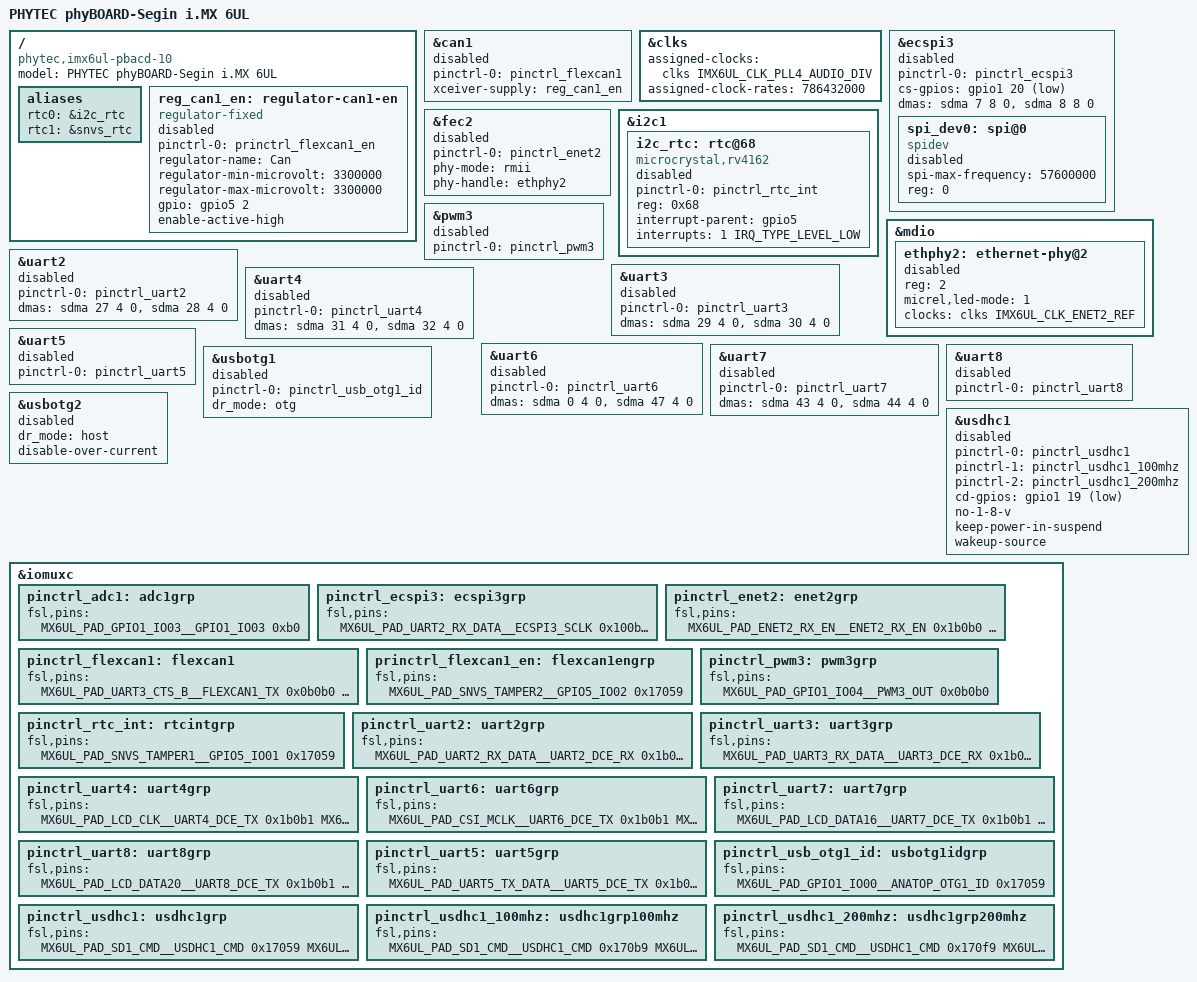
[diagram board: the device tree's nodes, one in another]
// SPDX-License-Identifier: (GPL-2.0+ OR MIT)
/*
 * Author: Llewellyn Fernandes <llewellynkbc@gmail.com>
 */

/ {

	model = "PHYTEC phyBOARD-Segin i.MX 6UL";
	compatible = "phytec,imx6ul-pbacd-10", "phytec,imx6ul-pcl063","fsl,imx6ul";

	aliases {
		rtc0 = &i2c_rtc;
		rtc1 = &snvs_rtc;
	};


	reg_can1_en: regulator-can1-en {
		compatible = "regulator-fixed";
		pinctrl-names = "default";
		pinctrl-0 = <&princtrl_flexcan1_en>;
		regulator-name = "Can";
		regulator-min-microvolt = <3300000>;
		regulator-max-microvolt = <3300000>;
		gpio = <&gpio5 2 GPIO_ACTIVE_HIGH>;
		enable-active-high;
		status = "disabled";
	};

};


&can1 {
	pinctrl-names = "default";
	pinctrl-0 = <&pinctrl_flexcan1>;
	xceiver-supply = <&reg_can1_en>;
	status = "disabled";
};

&clks {
	assigned-clocks = <&clks IMX6UL_CLK_PLL4_AUDIO_DIV>;
	assigned-clock-rates = <786432000>;
};


&ecspi3 {
	pinctrl-names = "default";
	pinctrl-0 = <&pinctrl_ecspi3>;
	cs-gpios = <&gpio1 20 GPIO_ACTIVE_LOW>;
	dmas = <&sdma 7 8 0>,
	       <&sdma 8 8 0>;
	dma-names = "rx", "tx";
	status = "disabled";

	spi_dev0: spi@0 {
		compatible = "spidev";
		spi-max-frequency = <57600000>;
		reg = <0>;
		status = "disabled";
	};
};

&fec2 {
	pinctrl-names = "default";
	pinctrl-0 = <&pinctrl_enet2>;
	phy-mode = "rmii";
	phy-handle = <&ethphy2>;
	status = "disabled";
};

&i2c1 {

	i2c_rtc: rtc@68 {
		pinctrl-names = "default";
		pinctrl-0 = <&pinctrl_rtc_int>;
		compatible = "microcrystal,rv4162";
		reg = <0x68>;
		interrupt-parent = <&gpio5>;
		interrupts = <1 IRQ_TYPE_LEVEL_LOW>;
		status = "disabled";
	};
};

&mdio {
	ethphy2: ethernet-phy@2 {
		reg = <2>;
		micrel,led-mode = <1>;
		clocks = <&clks IMX6UL_CLK_ENET2_REF>;
		clock-names = "rmii-ref";
		status = "disabled";
	};
};

&pwm3 {
	pinctrl-names = "default";
	pinctrl-0 = <&pinctrl_pwm3>;
	status = "disabled";
};


&uart2 {
	pinctrl-names = "default";
	pinctrl-0 = <&pinctrl_uart2>;
	dmas = <&sdma 27 4 0>,<&sdma 28 4 0>;
	dma-names = "rx","tx";
	status = "disabled";
};


&uart3 {
	pinctrl-names = "default";
	pinctrl-0 = <&pinctrl_uart3>;
	dmas = <&sdma 29 4 0>,<&sdma 30 4 0>;
	dma-names = "rx","tx";
	status = "disabled";
};


&uart4 {
	pinctrl-names = "default";
	pinctrl-0 = <&pinctrl_uart4>;
	dmas = <&sdma 31 4 0>,<&sdma 32 4 0>;
	dma-names = "rx","tx";
	status = "disabled";
};


&uart5 {
	pinctrl-names = "default";
	pinctrl-0 = <&pinctrl_uart5>;
	status = "disabled";
};


&uart6 {
	pinctrl-names = "default";
	pinctrl-0 = <&pinctrl_uart6>;
	dmas = <&sdma 0 4 0>,<&sdma 47 4 0>;
	dma-names = "rx","tx";
	status = "disabled";
};


&uart7 {
	pinctrl-names = "default";
	pinctrl-0 = <&pinctrl_uart7>;
	dmas = <&sdma 43 4 0>,<&sdma 44 4 0>;
	dma-names = "rx","tx";
	status = "disabled";
};


&uart8 {
	pinctrl-names = "default";
	pinctrl-0 = <&pinctrl_uart8>;
//	dmas = <&sdma 45 4 0>,<&sdma 46 4 0>;
//	dma-names = "rx","tx";
	status = "disabled";
};

&usbotg1 {
	pinctrl-names = "default";
	pinctrl-0 = <&pinctrl_usb_otg1_id>;
	dr_mode = "otg";
	status = "disabled";
};

&usbotg2 {
	dr_mode = "host";
	disable-over-current;
	status = "disabled";
};

&usdhc1 {
	pinctrl-names = "default", "state_100mhz", "state_200mhz";
	pinctrl-0 = <&pinctrl_usdhc1>;
	pinctrl-1 = <&pinctrl_usdhc1_100mhz>;
	pinctrl-2 = <&pinctrl_usdhc1_200mhz>;
	cd-gpios = <&gpio1 19 GPIO_ACTIVE_LOW>;
	no-1-8-v;
	keep-power-in-suspend;
	wakeup-source;
	status = "disabled";
};

&iomuxc {
	pinctrl_adc1: adc1grp {
		fsl,pins = <
			MX6UL_PAD_GPIO1_IO03__GPIO1_IO03	0xb0
		>;
	};

	pinctrl_ecspi3: ecspi3grp {
		fsl,pins = <
			MX6UL_PAD_UART2_RX_DATA__ECSPI3_SCLK	0x100b1
			MX6UL_PAD_UART2_RTS_B__ECSPI3_MISO	0x100b1
			MX6UL_PAD_UART2_CTS_B__ECSPI3_MOSI	0x100b1
			MX6UL_PAD_UART2_TX_DATA__GPIO1_IO20	0x10b0
		>;
	};

	pinctrl_enet2: enet2grp {
		fsl,pins = <
			MX6UL_PAD_ENET2_RX_EN__ENET2_RX_EN	0x1b0b0
			MX6UL_PAD_ENET2_RX_ER__ENET2_RX_ER	0x1b0b0
			MX6UL_PAD_ENET2_RX_DATA0__ENET2_RDATA00	0x1b0b0
			MX6UL_PAD_ENET2_RX_DATA1__ENET2_RDATA01	0x1b0b0
			MX6UL_PAD_ENET2_TX_EN__ENET2_TX_EN	0x1b010
			MX6UL_PAD_ENET2_TX_DATA0__ENET2_TDATA00	0x1b010
			MX6UL_PAD_ENET2_TX_DATA1__ENET2_TDATA01	0x1b010
			MX6UL_PAD_ENET2_TX_CLK__ENET2_REF_CLK2	0x4001b010
		>;
	};

	pinctrl_flexcan1: flexcan1 {
		fsl,pins = <
			MX6UL_PAD_UART3_CTS_B__FLEXCAN1_TX	0x0b0b0
			MX6UL_PAD_UART3_RTS_B__FLEXCAN1_RX	0x0b0b0
		>;
	};

	princtrl_flexcan1_en: flexcan1engrp {
		fsl,pins = <
			MX6UL_PAD_SNVS_TAMPER2__GPIO5_IO02	0x17059
		>;
	};

	pinctrl_pwm3: pwm3grp {
		fsl,pins = <
			MX6UL_PAD_GPIO1_IO04__PWM3_OUT	0x0b0b0
		>;
	};

	pinctrl_rtc_int: rtcintgrp {
		fsl,pins = <
			MX6UL_PAD_SNVS_TAMPER1__GPIO5_IO01	0x17059
		>;
	};

		pinctrl_uart2: uart2grp {
         fsl,pins = <
             MX6UL_PAD_UART2_RX_DATA__UART2_DCE_RX		0x1b0b1
             MX6UL_PAD_UART2_TX_DATA__UART2_DCE_TX		0x1b0b1
         >;
     };

    pinctrl_uart3: uart3grp {
         fsl,pins = <
             MX6UL_PAD_UART3_RX_DATA__UART3_DCE_RX		0x1b0b1
             MX6UL_PAD_UART3_TX_DATA__UART3_DCE_TX		0x1b0b1
         >;
    };

    pinctrl_uart4: uart4grp {
         fsl,pins = <
             MX6UL_PAD_LCD_CLK__UART4_DCE_TX			0x1b0b1
             MX6UL_PAD_LCD_ENABLE__UART4_DCE_RX			0x1b0b1
         >;
    };

	pinctrl_uart6: uart6grp {
         fsl,pins = <
             MX6UL_PAD_CSI_MCLK__UART6_DCE_TX			0x1b0b1
             MX6UL_PAD_CSI_PIXCLK__UART6_DCE_RX			0x1b0b1
         >;
    };

    pinctrl_uart7: uart7grp {
		fsl,pins = <
			MX6UL_PAD_LCD_DATA16__UART7_DCE_TX			0x1b0b1
			MX6UL_PAD_LCD_DATA17__UART7_DCE_RX			0x1b0b1
		>;
	};
	pinctrl_uart8: uart8grp {
		fsl,pins = <
			MX6UL_PAD_LCD_DATA20__UART8_DCE_TX			0x1b0b1
			MX6UL_PAD_LCD_DATA21__UART8_DCE_RX			0x1b0b1
		>;
	};

	pinctrl_uart5: uart5grp {
		fsl,pins = <
			MX6UL_PAD_UART5_TX_DATA__UART5_DCE_TX	0x1b0b1
			MX6UL_PAD_UART5_RX_DATA__UART5_DCE_RX	0x1b0b1
			MX6UL_PAD_GPIO1_IO08__UART5_DCE_RTS	0x1b0b1
			MX6UL_PAD_GPIO1_IO09__UART5_DCE_CTS	0x1b0b1
		>;
	};

	pinctrl_usb_otg1_id: usbotg1idgrp {
		fsl,pins = <
			MX6UL_PAD_GPIO1_IO00__ANATOP_OTG1_ID	0x17059
		>;
	};

	pinctrl_usdhc1: usdhc1grp {
		fsl,pins = <
			MX6UL_PAD_SD1_CMD__USDHC1_CMD		0x17059
			MX6UL_PAD_SD1_CLK__USDHC1_CLK		0x10059
			MX6UL_PAD_SD1_DATA0__USDHC1_DATA0	0x17059
			MX6UL_PAD_SD1_DATA1__USDHC1_DATA1	0x17059
			MX6UL_PAD_SD1_DATA2__USDHC1_DATA2	0x17059
			MX6UL_PAD_SD1_DATA3__USDHC1_DATA3	0x17059
			MX6UL_PAD_UART1_RTS_B__GPIO1_IO19	0x17059
		>;
	};

	pinctrl_usdhc1_100mhz: usdhc1grp100mhz {
		fsl,pins = <
			MX6UL_PAD_SD1_CMD__USDHC1_CMD		0x170b9
			MX6UL_PAD_SD1_CLK__USDHC1_CLK		0x100b9
			MX6UL_PAD_SD1_DATA0__USDHC1_DATA0	0x170b9
			MX6UL_PAD_SD1_DATA1__USDHC1_DATA1	0x170b9
			MX6UL_PAD_SD1_DATA2__USDHC1_DATA2	0x170b9
			MX6UL_PAD_SD1_DATA3__USDHC1_DATA3	0x170b9
		>;
	};

	pinctrl_usdhc1_200mhz: usdhc1grp200mhz {
		fsl,pins = <
			MX6UL_PAD_SD1_CMD__USDHC1_CMD		0x170f9
			MX6UL_PAD_SD1_CLK__USDHC1_CLK		0x100f9
			MX6UL_PAD_SD1_DATA0__USDHC1_DATA0	0x170f9
			MX6UL_PAD_SD1_DATA1__USDHC1_DATA1	0x170f9
			MX6UL_PAD_SD1_DATA2__USDHC1_DATA2	0x170f9
			MX6UL_PAD_SD1_DATA3__USDHC1_DATA3	0x170f9
		>;
	};
};
